# CM4 register map
CPU: CM4 r0p1, selectable endian, MPU, FPU, 3 interrupt priority bits
Registers are 32-bit, read-write, reset 0x0 unless marked. A register's access mark holds for its fields unless they carry their own. Offsets are from the block's base; lines under a group give offsets from that group; [hi:lo] are bit positions; {n}, {i} and the like mark numbered series; 'fields as' and 'values as' point back to an identical list; <NAME> marks a mode.

## Memory map
0xE0000000 ITM size 0x1000 — Instrumentation Macrocell
0xE0001000 DWT size 0x1000 — Data Watchpoint and Trace
0xE0002000 DPB size 0x1000 — Flash Patch and Breakpoint
0xE000E004 ICB size 0xC — Implementation Control Block
0xE000E010 SYSTICK size 0x10 — SysTick Timer
0xE000E100 NVIC size 0x4F0 — Nested Vectored Interrupt Controller
0xE000ED00 SCB size 0x90 — System Control Block
0xE000ED90 MPU size 0x2C — Memory Protection Unit
0xE000EDF0 DCB size 0x10 — Debug Control Block
0xE000EF00 SIG size 0x4 — Software Interrupt Generation
0xE000EF34 FP size 0x18 — Floating-Point Extension
0xE000EF50 CMO size 0x2C — Cache Maintenance Operations
0xE0040000 TPIU size 0x1000 — Trace Port Interface Unit

## ITM — Instrumentation Macrocell
Base 0xE0000000
{0x0+4i} Stimulus Port Register {i} (i=0..255) — Provides the interface for generating instrumentation messages
  [31:0] STIMULUS — Data write to the stimulus port FIFO, for forwarding as a software event packet
  [0] FIFOREADY — Indicates whether the stimulus port FIFO can accept data
    0=Stimulus port FIFO full; 1=Stimulus port FIFO can accept at least one word
{0xE00+4i} Trace Enable Register {i} (i=0..7) — Provide an individual enable bit for each ITM_STIM register
  [31:0] STIMENA — For bit STIMENA[n], in register ITM_TERx
    0=Stimulus port (32x + n) disabled; 1=Stimulus port (32x + n) enabled
0xE40 Trace Privilege Register — Controls which stimulus ports can be accessed by unprivileged code
  [31:0] PRIVMASK — Bit mask to enable unprivileged access to ITM stimulus ports
    0=Unprivileged access permitted; 1=Privileged access only
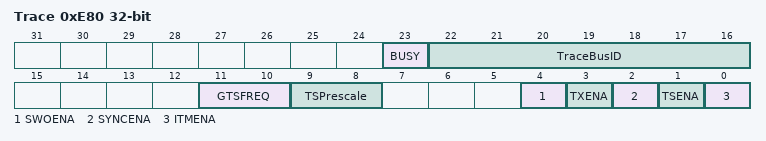
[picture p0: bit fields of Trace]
0xE80 Trace Control Register — Configures and controls transfers through the ITM interface
  [23] BUSY — Indicates whether the ITM is currently processing events
    0=ITM is not processing any events; 1=ITM events present and being drained
  [22:16] TraceBusID — Identifier for multi-source trace stream formatting
  [11:10] GTSFREQ — Global timestamp frequency
    0=Disable generation of global timestamps; 1=Generate timestamp request whenever the ITM detects a change in global timestamp counter bits[47:7]; 10=Generate timestamp request whenever the ITM detects a change in global timestamp counter bits[47:13]; 11=Generate a timestamp after every packet, if the output FIFO is empty
  [9:8] TSPrescale — Local timestamp prescaler, used with the trace packet reference clock
    0=No prescaling; 1=Divide by 4; 10=Divide by 16; 11=Divide by 64
  [4] SWOENA — Enables asynchronous clocking of the timestamp counter
    0=Timestamp counter uses the processor system clock; 1=Timestamp counter uses asynchronous clock from the TPIU interface
  [3] TXENA — Enables forwarding of hardware event packet from the DWT unit to the ITM for output to the TPIU
    0=Disabled; 1=Enabled
  [2] SYNCENA — Enables Synchronization packet transmission for a synchronous TPIU
    0=Disabled; 1=Enabled
  [1] TSENA — Enables Local timestamp generation
    0=Disabled; 1=Enabled
  [0] ITMENA — Enables the ITM

## DPB — Flash Patch and Breakpoint
Base 0xE0002000
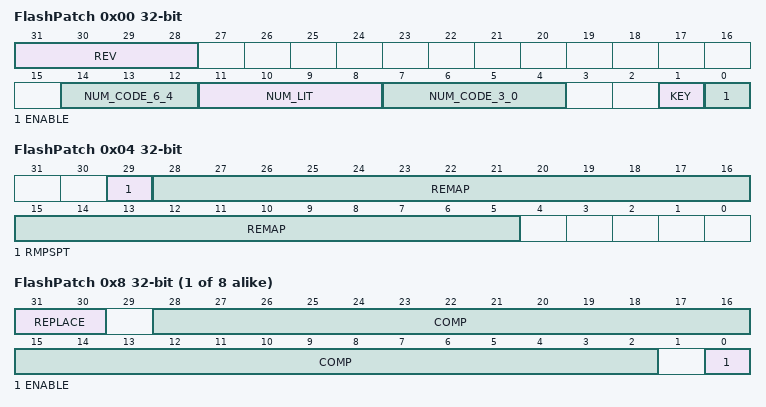
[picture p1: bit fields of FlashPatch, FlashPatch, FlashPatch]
0x00 FlashPatch Control Register — Provides FPB implementation information, and the global enable for the FPB unit
  [31:28] REV — Flash Patch Breakpoint architecture revision
    0=Flash Patch Breakpoint version 1; 1=Flash Patch Breakpoint version 2
  [14:12] NUM_CODE_6_4 — Number of comperators 6:4
  [11:8] NUM_LIT — The number of literal address comparators supported, starting from NUM_CODE upwards
  [7:4] NUM_CODE_3_0 — Number of comperators 3:0
  [1] KEY — On any write to FP_CTRL, this bit must be 1
  [0] ENABLE — Enable bit for the FPB
    0=Flash Patch Breakpoint disabled; 1=Flash Patch Breakpoint enabled
0x04 FlashPatch Remap register — Indicates whether the implementation supports flash patch remap, and if it does, holds the SRAM address for remap
  [29] RMPSPT — Indicates whether the FPB unit supports flash patch remap
    0=Remapping not supported. The FPB only supports breakpoint functionality; 1=Hard-wired remap to SRAM region
  [28:5] REMAP — If the FPB supports flash patch remap, this field
{0x8+4i} FlashPatch Comparator Register {i} (i=0..7) — Holds an address for comparison with addresses in the Code memory region
  [31:30] REPLACE — For an instruction address comparator
    0=Remap to remap address; 1=Breakpoint on instruction at '000':COMP:'00'; 10=Breakpoint on instruction at '000':COMP:'10'; 11=Breakpoint on both instructions at '000':COMP:'00' and '000':COMP:'10'
  [28:2] COMP — Bits[28
  [0] ENABLE — Enable bit for this comparator
    0=Comparator disabled; 1=Comparator enabled
